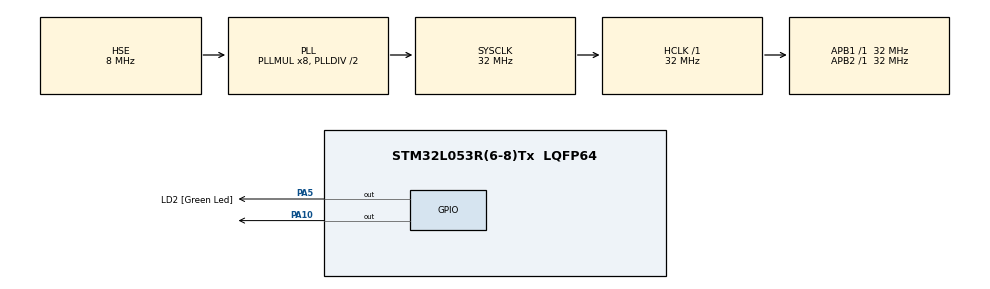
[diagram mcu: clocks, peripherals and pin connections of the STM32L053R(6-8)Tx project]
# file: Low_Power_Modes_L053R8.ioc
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Mcu.Family=STM32L0
Mcu.Name=STM32L053R(6-8)Tx
Mcu.Package=LQFP64
NVIC.RTC_IRQn=true\:0\:0\:false\:false\:true\:true\:true\:true
PA10.Signal=GPIO_Output
PA5.GPIO_Label=LD2 [Green Led]
PA5.Signal=GPIO_Output
PC13.Signal=RTC_OUT_CALIB
PC14-OSC32_IN.Mode=LSE-External-Oscillator
PC14-OSC32_IN.Signal=RCC_OSC32_IN
PC15-OSC32_OUT.Mode=LSE-External-Oscillator
PC15-OSC32_OUT.Signal=RCC_OSC32_OUT
PH0-OSC_IN.Mode=HSE-External-Clock-Source
PH0-OSC_IN.Signal=RCC_OSC_IN
PH1-OSC_OUT.Signal=RCC_OSC_OUT
ProjectManager.HeapSize=0x200
ProjectManager.StackSize=0x400
ProjectManager.TargetToolchain=STM32CubeIDE
RCC.AHBFreq_Value=32000000
RCC.APB1Freq_Value=32000000
RCC.APB1TimFreq_Value=32000000
RCC.APB2Freq_Value=32000000
RCC.APB2TimFreq_Value=32000000
RCC.HCLKFreq_Value=32000000
RCC.HSE_VALUE=8000000
RCC.HSI16_VALUE=16000000
RCC.HSI48_VALUE=48000000
RCC.HSI_VALUE=16000000
RCC.MSI_VALUE=2097000
RCC.PLLMUL=RCC_PLLMUL_8
RCC.PLLSourceVirtual=RCC_PLLSOURCE_HSE
RCC.RTCClockSelection=RCC_RTCCLKSOURCE_LSE
RCC.RTCClockSelectionVirtual=RCC_RTCCLKSOURCE_LSE
RCC.SYSCLKFreq_VALUE=32000000
RCC.SYSCLKSource=RCC_SYSCLKSOURCE_PLLCLK
RCC.VCOOutputFreq_Value=64000000
RTC.WakeUpClock-WakeUp=RTC_WAKEUPCLOCK_CK_SPRE_16BITS
RTC.WakeUpCounter-WakeUp=5
VP_RTC_VS_RTC_Activate.Mode=RTC_Enabled
VP_RTC_VS_RTC_WakeUp_intern.Mode=WakeUp
board=NUCLEO-L053R8

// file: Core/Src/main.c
/* USER CODE BEGIN Header */
/**
  ******************************************************************************
  * @file           : main.c
  * @brief          : Main program body
  ******************************************************************************
  * @attention
  *
  * Copyright (c) 2024 STMicroelectronics.
  * All rights reserved.
  *
  * This software is licensed under terms that can be found in the LICENSE file
  * in the root directory of this software component.
  * If no LICENSE file comes with this software, it is provided AS-IS.
  *
  ******************************************************************************
  */
/* USER CODE END Header */
#include "main.h"

RTC_HandleTypeDef hrtc;

void SystemClock_Config(void);
static void MX_GPIO_Init(void);
static void MX_RTC_Init(void);

int main(void)
{

  /* MCU Configuration--------------------------------------------------------*/

  /* Reset of all peripherals, Initializes the Flash interface and the Systick. */
  HAL_Init();

  /* Configure the system clock */
  SystemClock_Config();

  /* Initialize all configured peripherals */
  MX_GPIO_Init();
  MX_RTC_Init();

  /* Infinite loop */
  while (1)
  {

    /* USER CODE BEGIN 3 */
	HAL_GPIO_WritePin(GPIOA, GPIO_PIN_10, GPIO_PIN_SET);

	/* Enable Ultra low power mode */
	HAL_PWREx_EnableUltraLowPower();

	/* Enable the fast wake up from Ultra low power mode */
	HAL_PWREx_EnableFastWakeUp();

	/*Clear all related wakeup flags*/
	__HAL_PWR_CLEAR_FLAG(PWR_FLAG_WU);

	HAL_GPIO_WritePin(GPIOA, GPIO_PIN_10, GPIO_PIN_RESET);

	/*Enter the Standby mode*/
	HAL_SuspendTick();
	HAL_PWR_EnterSTOPMode(PWR_LOWPOWERREGULATOR_ON, PWR_STOPENTRY_WFI);
	//HAL_PWR_EnterSTANDBYMode();

	SystemClock_Config ();
	HAL_ResumeTick();
  }
  /* USER CODE END 3 */
}

void SystemClock_Config(void)
{
  RCC_OscInitTypeDef RCC_OscInitStruct = {0};
  RCC_ClkInitTypeDef RCC_ClkInitStruct = {0};
  RCC_PeriphCLKInitTypeDef PeriphClkInit = {0};

  /** Configure the main internal regulator output voltage
  */
  __HAL_PWR_VOLTAGESCALING_CONFIG(PWR_REGULATOR_VOLTAGE_SCALE1);

  /** Configure LSE Drive Capability
  */
  HAL_PWR_EnableBkUpAccess();
  __HAL_RCC_LSEDRIVE_CONFIG(RCC_LSEDRIVE_LOW);

  /** Initializes the RCC Oscillators according to the specified parameters
  * in the RCC_OscInitTypeDef structure.
  */
  RCC_OscInitStruct.OscillatorType = RCC_OSCILLATORTYPE_HSE|RCC_OSCILLATORTYPE_LSE;
  RCC_OscInitStruct.HSEState = RCC_HSE_BYPASS;
  RCC_OscInitStruct.LSEState = RCC_LSE_ON;
  RCC_OscInitStruct.PLL.PLLState = RCC_PLL_ON;
  RCC_OscInitStruct.PLL.PLLSource = RCC_PLLSOURCE_HSE;
  RCC_OscInitStruct.PLL.PLLMUL = RCC_PLLMUL_8;
  RCC_OscInitStruct.PLL.PLLDIV = RCC_PLLDIV_2;
  if (HAL_RCC_OscConfig(&RCC_OscInitStruct) != HAL_OK)
  {
    Error_Handler();
  }

  /** Initializes the CPU, AHB and APB buses clocks
  */
  RCC_ClkInitStruct.ClockType = RCC_CLOCKTYPE_HCLK|RCC_CLOCKTYPE_SYSCLK
                              |RCC_CLOCKTYPE_PCLK1|RCC_CLOCKTYPE_PCLK2;
  RCC_ClkInitStruct.SYSCLKSource = RCC_SYSCLKSOURCE_PLLCLK;
  RCC_ClkInitStruct.AHBCLKDivider = RCC_SYSCLK_DIV1;
  RCC_ClkInitStruct.APB1CLKDivider = RCC_HCLK_DIV1;
  RCC_ClkInitStruct.APB2CLKDivider = RCC_HCLK_DIV1;

  if (HAL_RCC_ClockConfig(&RCC_ClkInitStruct, FLASH_LATENCY_1) != HAL_OK)
  {
    Error_Handler();
  }
  PeriphClkInit.PeriphClockSelection = RCC_PERIPHCLK_RTC;
  PeriphClkInit.RTCClockSelection = RCC_RTCCLKSOURCE_LSE;
  if (HAL_RCCEx_PeriphCLKConfig(&PeriphClkInit) != HAL_OK)
  {
    Error_Handler();
  }
}

static void MX_RTC_Init(void)
{

  /** Initialize RTC Only
  */
  hrtc.Instance = RTC;
  hrtc.Init.HourFormat = RTC_HOURFORMAT_24;
  hrtc.Init.AsynchPrediv = 127;
  hrtc.Init.SynchPrediv = 255;
  hrtc.Init.OutPut = RTC_OUTPUT_DISABLE;
  hrtc.Init.OutPutRemap = RTC_OUTPUT_REMAP_NONE;
  hrtc.Init.OutPutPolarity = RTC_OUTPUT_POLARITY_HIGH;
  hrtc.Init.OutPutType = RTC_OUTPUT_TYPE_OPENDRAIN;
  if (HAL_RTC_Init(&hrtc) != HAL_OK)
  {
    Error_Handler();
  }

  /** Enable the WakeUp
  */
  if (HAL_RTCEx_SetWakeUpTimer_IT(&hrtc, 5, RTC_WAKEUPCLOCK_CK_SPRE_16BITS) != HAL_OK)
  {
    Error_Handler();
  }

}

static void MX_GPIO_Init(void)
{
  GPIO_InitTypeDef GPIO_InitStruct = {0};

  /* GPIO Ports Clock Enable */
  __HAL_RCC_GPIOC_CLK_ENABLE();
  __HAL_RCC_GPIOH_CLK_ENABLE();
  __HAL_RCC_GPIOA_CLK_ENABLE();
  __HAL_RCC_GPIOB_CLK_ENABLE();
  __HAL_RCC_GPIOD_CLK_ENABLE();

  /*Configure GPIO pin Output Level */
  HAL_GPIO_WritePin(GPIOA, LD2_Pin|GPIO_PIN_10, GPIO_PIN_RESET);

  /*Configure GPIO pins : PC0 PC1 PC2 PC3
                           PC4 PC5 PC6 PC7
                           PC8 PC9 PC10 PC11
                           PC12 */
  GPIO_InitStruct.Pin = GPIO_PIN_0|GPIO_PIN_1|GPIO_PIN_2|GPIO_PIN_3
                          |GPIO_PIN_4|GPIO_PIN_5|GPIO_PIN_6|GPIO_PIN_7
                          |GPIO_PIN_8|GPIO_PIN_9|GPIO_PIN_10|GPIO_PIN_11
                          |GPIO_PIN_12;
  GPIO_InitStruct.Mode = GPIO_MODE_ANALOG;
  GPIO_InitStruct.Pull = GPIO_NOPULL;
  HAL_GPIO_Init(GPIOC, &GPIO_InitStruct);

  /*Configure GPIO pins : PA0 PA1 PA2 PA3
                           PA4 PA6 PA7 PA8
                           PA9 PA11 PA12 PA13
                           PA14 PA15 */
  GPIO_InitStruct.Pin = GPIO_PIN_0|GPIO_PIN_1|GPIO_PIN_2|GPIO_PIN_3
                          |GPIO_PIN_4|GPIO_PIN_6|GPIO_PIN_7|GPIO_PIN_8
                          |GPIO_PIN_9|GPIO_PIN_11|GPIO_PIN_12|GPIO_PIN_13
                          |GPIO_PIN_14|GPIO_PIN_15;
  GPIO_InitStruct.Mode = GPIO_MODE_ANALOG;
  GPIO_InitStruct.Pull = GPIO_NOPULL;
  HAL_GPIO_Init(GPIOA, &GPIO_InitStruct);

  /*Configure GPIO pins : LD2_Pin PA10 */
  GPIO_InitStruct.Pin = LD2_Pin|GPIO_PIN_10;
  GPIO_InitStruct.Mode = GPIO_MODE_OUTPUT_PP;
  GPIO_InitStruct.Pull = GPIO_NOPULL;
  GPIO_InitStruct.Speed = GPIO_SPEED_FREQ_LOW;
  HAL_GPIO_Init(GPIOA, &GPIO_InitStruct);

  /*Configure GPIO pins : PB0 PB1 PB2 PB10
                           PB11 PB12 PB13 PB14
                           PB15 PB3 PB4 PB5
                           PB6 PB7 PB8 PB9 */
  GPIO_InitStruct.Pin = GPIO_PIN_0|GPIO_PIN_1|GPIO_PIN_2|GPIO_PIN_10
                          |GPIO_PIN_11|GPIO_PIN_12|GPIO_PIN_13|GPIO_PIN_14
                          |GPIO_PIN_15|GPIO_PIN_3|GPIO_PIN_4|GPIO_PIN_5
                          |GPIO_PIN_6|GPIO_PIN_7|GPIO_PIN_8|GPIO_PIN_9;
  GPIO_InitStruct.Mode = GPIO_MODE_ANALOG;
  GPIO_InitStruct.Pull = GPIO_NOPULL;
  HAL_GPIO_Init(GPIOB, &GPIO_InitStruct);

  /*Configure GPIO pin : PD2 */
  GPIO_InitStruct.Pin = GPIO_PIN_2;
  GPIO_InitStruct.Mode = GPIO_MODE_ANALOG;
  GPIO_InitStruct.Pull = GPIO_NOPULL;
  HAL_GPIO_Init(GPIOD, &GPIO_InitStruct);

}

void Error_Handler(void)
{
  __disable_irq();
  while (1)
  {
  }
}
